VERSION ""

NS_ :

BS_:

BU_: ECU_Moteur ECU_Dashboard

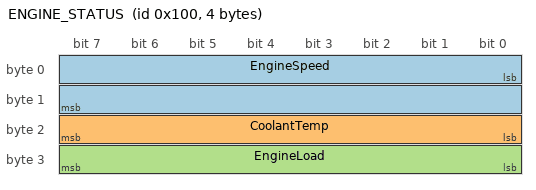
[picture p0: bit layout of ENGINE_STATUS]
BO_ 256 ENGINE_STATUS: 4 ECU_Moteur
 SG_ EngineSpeed : 0|16@1+ (1,0) [0|8000] "rpm" ECU_Dashboard
 SG_ CoolantTemp : 16|8@1+ (1,-40) [-40|215] "degC" ECU_Dashboard
 SG_ EngineLoad : 24|8@1+ (0.5,0) [0|100] "%" ECU_Dashboard

BO_ 512 DASH_REQUEST: 1 ECU_Dashboard
 SG_ DisplayMode : 0|8@1+ (1,0) [0|3] "" ECU_Moteur
